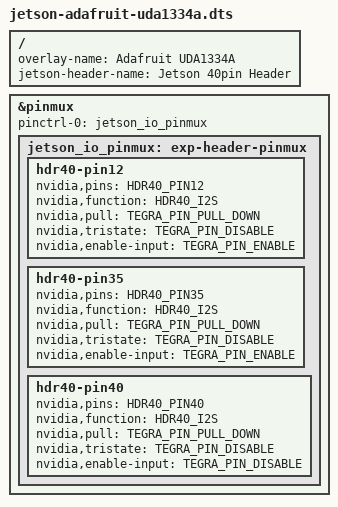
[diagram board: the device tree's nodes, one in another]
// SPDX-License-Identifier: GPL-2.0-only
/*
 * Jetson Device-tree overlay for Adafruit I2S Stereo Decoder Breakout
 * (UDA1334A).
 *
 * Copyright (c) 2021 NVIDIA CORPORATION. All rights reserved.
 *
 */

#include <dt-bindings/pinctrl/pinctrl-tegra.h>

/ {
	overlay-name = "Adafruit UDA1334A";
	jetson-header-name = "Jetson 40pin Header";
	compatible = JETSON_COMPATIBLE;

	fragment@0 {
		target = <&pinmux>;
		__overlay__ {
			pinctrl-names = "default";
			pinctrl-0 = <&jetson_io_pinmux>;

			jetson_io_pinmux: exp-header-pinmux {
				hdr40-pin12 {
					nvidia,pins = HDR40_PIN12;
					nvidia,function = HDR40_I2S;
					nvidia,pull = <TEGRA_PIN_PULL_DOWN>;
					nvidia,tristate = <TEGRA_PIN_DISABLE>;
					nvidia,enable-input = <TEGRA_PIN_ENABLE>;
				};

				hdr40-pin35 {
					nvidia,pins = HDR40_PIN35;
					nvidia,function = HDR40_I2S;
					nvidia,pull = <TEGRA_PIN_PULL_DOWN>;
					nvidia,tristate = <TEGRA_PIN_DISABLE>;
					nvidia,enable-input = <TEGRA_PIN_ENABLE>;
				};

				hdr40-pin40 {
					nvidia,pins = HDR40_PIN40;
					nvidia,function = HDR40_I2S;
					nvidia,pull = <TEGRA_PIN_PULL_DOWN>;
					nvidia,tristate = <TEGRA_PIN_DISABLE>;
					nvidia,enable-input = <TEGRA_PIN_DISABLE>;
				};
			};
		};
	};
};
